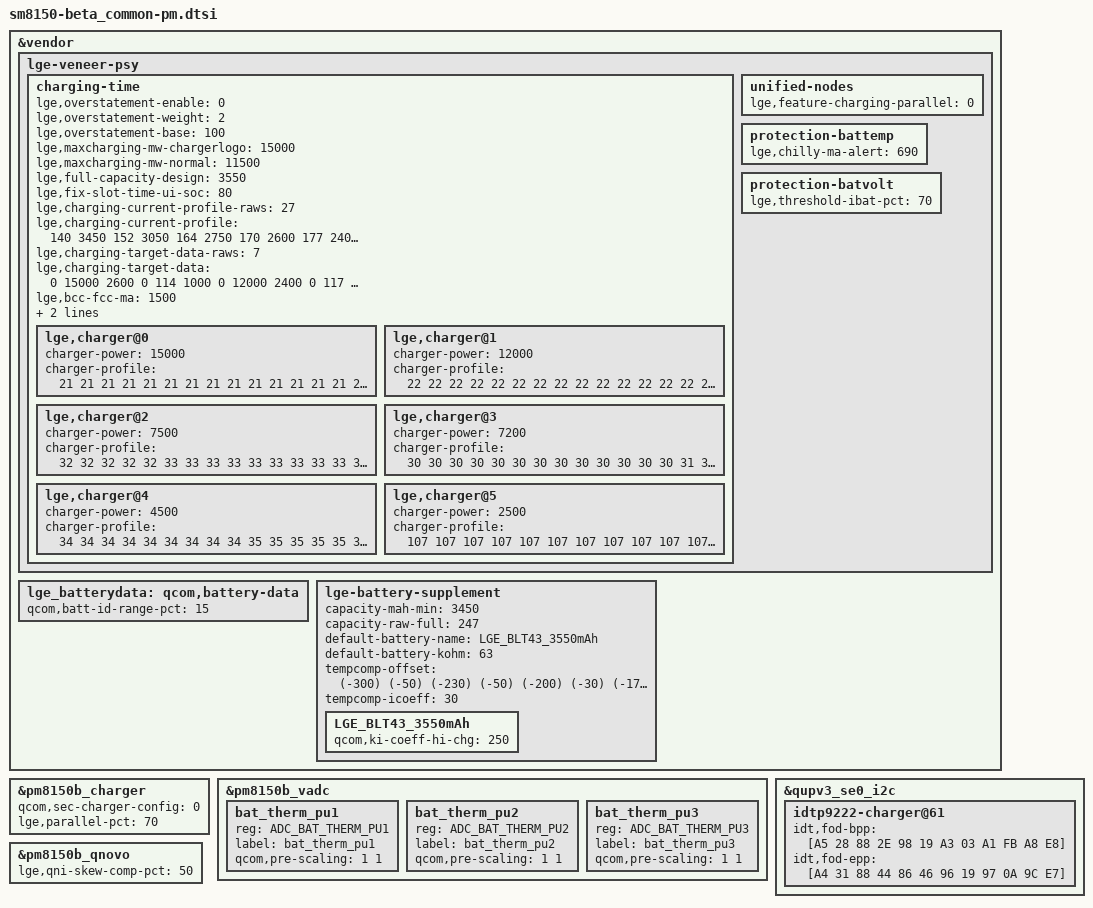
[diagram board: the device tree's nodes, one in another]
/*
 * Copyright (c) 2018, The Linux Foundation. All rights reserved.
 *
 * This program is free software; you can redistribute it and/or modify
 * it under the terms of the GNU General Public License version 2 and
 * only version 2 as published by the Free Software Foundation.
 *
 * This program is distributed in the hope that it will be useful,
 * but WITHOUT ANY WARRANTY; without even the implied warranty of
 * MERCHANTABILITY or FITNESS FOR A PARTICULAR PURPOSE.  See the
 * GNU General Public License for more details.
 */
#include "../../sm8150_common/sm8150_common-pm.dtsi"
&vendor {
	lge-veneer-psy {
		charging-time {
			#address-cells = <1>;
			#size-cells = <0>;
			lge,overstatement-enable = <0>;
			lge,overstatement-weight = <2>;
			lge,overstatement-base = <100>;

			lge,maxcharging-mw-chargerlogo = <15000>;
			lge,maxcharging-mw-normal = <11500>;

			lge,full-capacity-design = <3550>;
			lge,fix-slot-time-ui-soc = <80>;
			lge,charging-current-profile-raws = <27>;
			lge,charging-current-profile = <
				/* format: raw_soc, raw_current(mA) */
				/* CC */
				140  3450
				152  3050
				164  2750
				170  2600
				177  2400
				191  2100
				207  1650
				219  1300
				225  1100
				228  1050
				231  900
				/* cv - ui 94% */
				232  880
				233  860
				234  840
				235  810
				236  790
				237  735
				238  690
				239  660
				240  640
				241  615
				242  560
				243  530
				244  505
				245  470
				246  450
				247  430   /* <- END -> */
			>;

			lge,charging-target-data-raws = <7>;
			lge,charging-target-data = <
			/* format : type, power(mW), current(mA), down(uA), target(min), no_dd_decipct */
			/* type-wired: chargerlogo */   0    15000    2600       0    114    1000
			/* type-wired: power on    */   0    12000    2400       0    117    1000
			/* type-wired: DCP         */   0     7500    1650    1100    154    1000
			/* type-wired: SDP         */   0     2500     500       0    435    1000
			/* type-wireless: EPP      */   1     7200    1480    4100    205    1000
			/* type-wireless: BPP      */   1     4500    1060    2600    230    1000
			/* type-BCC                */   2     7500    1500       0    157    1000
			>;


			// BCC
			lge,bcc-fcc-ma = <1500>;
			bcc-charger-profile = <
				35  35  35  35  35  35  35  35  35  35  35  35  35  35  35  35
				35  35  35  35  35  35  35  35  35  35  35  35  35  35  35  35
				35  35  35  35  35  35  35  35  35  35  35  35  35  35  35  35
				35  35  35  35  35  35  35  35  35  35  35  35  35  35  35  35
				35  35  35  35  35  35  35  35  35  35  35  35  35  35  35  35
				35  35  35  35  35  35  35  35  35  35  35  35  35  35  35  35
				35  35  35  35  35  35  35  35  35  35  35  35  35  35  35  35
				35  35  35  35  35  35  35  35  35  35  35  35  35  35  35  35
				35  35  35  35  35  35  35  35  35  35  35  35  35  35  35  35
				35  35  35  35  35  35  35  35  35  35  35  35  35  35  35  35
				35  35  35  35  35  35  35  35  35  35  35  35  35  35  35  35
				35  35  35  35  35  35  35  35  35  35  35  35  35  35  35  35
				35  35  35  35  35  35  35  35  35  35  35  35  35  35  35  35
				35  35  35  35  35  35  35  36  37  38  39  40  41  42  43  45
				46  47  49  51  52  54  56  58  60  63  66  68  72  75  79  83
				88  93  99 106 114 123 134 148 148 148 148 148 148 148 148 148
			>;

			lge,charger@0 {		//  fast charger: 9V * 1.66A or 5V * 3A = 15W
				charger-power = <15000>;
				charger-profile = <
					21  21  21  21  21  21  21  21  21  21  21  21  21  21  21  21
					21  21  21  21  21  21  21  21  21  21  21  21  21  21  21  21
					21  21  21  21  21  21  21  21  21  21  21  21  21  21  21  21
					21  21  21  21  21  21  21  21  21  21  21  21  21  21  21  21
					21  21  21  21  21  21  21  21  21  21  21  21  21  21  21  21
					21  21  21  21  21  21  21  21  21  21  21  21  21  21  21  21
					21  21  21  21  21  21  21  21  21  21  21  21  21  21  21  21
					21  21  21  21  21  21  21  21  21  21  21  21  21  21  21  21
					21  21  21  21  21  21  21  21  21  21  21  21  21  21  21  21
					23  23  23  23  23  23  23  23  23  23  23  23  23  23  23  23
					23  23  23  23  23  23  23  23  23  23  23  23  23  23  23  23
					23  23  26  26  26  26  26  26  26  26  26  26  26  26  26  26
					33  33  33  33  33  33  33  33  33  33  33  33  33  33  33  33
					33  33  42  42  42  42  42  42  42  42  42  42  42  49  49  49
					49  49  49  51  60  61  63  64  66  68  69  71  73  75  77  79
					82  84  87  90  93  96 100 104 104 104 104 104 104 104 104 104
				>;
			};
			lge,charger@1 {		//  power-on fast charger: 2.4A * 4.0V / 80% = 12W
				charger-power = <12000>;
				charger-profile = <
					22  22  22  22  22  22  22  22  22  22  22  22  22  22  22  22
					22  22  22  22  22  22  22  22  22  22  22  22  22  22  22  22
					22  22  22  22  22  22  22  22  22  22  22  22  22  22  22  22
					22  22  22  22  22  22  22  22  22  22  22  22  22  22  22  22
					22  22  22  22  22  22  22  22  22  22  22  22  22  22  22  22
					22  22  22  22  22  22  22  22  22  22  22  22  22  22  22  22
					22  22  22  22  22  22  22  22  22  22  22  22  22  22  22  22
					22  22  22  22  22  22  22  22  22  22  22  22  22  22  22  22
					22  22  22  22  22  22  22  22  22  22  22  22  22  22  22  22
					22  22  22  22  22  22  22  22  22  22  22  22  22  22  22  22
					22  22  22  22  22  22  22  22  22  22  22  22  22  22  22  22
					22  22  26  26  26  26  26  26  26  26  26  26  26  26  26  26
					33  33  33  33  33  33  33  33  33  33  33  33  33  33  33  33
					41  41  41  41  41  41  41  41  41  41  41  49  49  49  49  49
					49  51  51  51  60  61  63  64  66  67  69  71  73  75  77  79
					81  84  87  90  93  96 100 103 103 103 103 103 103 103 103 103
				>;
			};
			lge,charger@2 {		//  dcp charger: 5V * 1500mA = 7.5W
				charger-power = <7500>;
				charger-profile = <
					32  32  32  32  32  33  33  33  33  33  33  33  33  33  33  33
					33  33  33  33  33  33  33  33  33  33  33  33  33  33  33  33
					33  33  33  33  33  33  33  33  33  33  33  33  33  33  33  33
					33  33  33  33  33  33  33  33  33  33  33  34  34  34  34  34
					34  34  34  34  34  34  34  34  34  34  34  34  34  34  34  34
					34  34  34  34  34  34  34  34  34  34  34  34  34  34  34  34
					34  34  34  34  34  34  34  34  34  34  34  34  34  35  35  35
					35  35  35  35  35  35  35  35  35  35  35  35  35  35  35  35
					35  35  35  35  35  35  35  35  35  35  35  35  35  35  35  35
					35  35  35  35  35  35  35  35  35  35  35  35  35  36  36  36
					36  36  36  36  36  36  36  36  36  36  36  36  36  36  36  36
					36  36  36  36  36  36  36  36  36  36  36  36  36  36  36  36
					36  36  36  36  36  36  36  36  36  36  37  37  37  37  37  37
					37  37  37  37  37  37  37  37  38  39  40  41  42  43  44  45
					47  48  50  51  53  55  57  59  61  64  66  69  73  76  80  84
					89  94 100 107 115 124 135 150 150 150 150 150 150 150 150 150
				>;
			};
			lge,charger@3 {		// EPP wireless charger: 9000mV * 800mA = 7.2W
				charger-power = <7200>;
				charger-profile = <
					30  30  30  30  30  30  30  30  30  30  30  30  30  31  31  31
					31  31  31  31  31  31  31  31  31  32  32  32  32  32  32  32
					32  32  32  32  33  33  33  33  33  33  33  33  33  33  34  34
					34  34  34  34  34  34  34  35  35  35  35  35  35  35  35  35
					36  36  36  36  36  36  36  36  36  37  37  37  37  37  37  37
					37  38  38  38  38  38  38  38  39  39  39  39  39  39  39  39
					40  40  40  40  40  40  41  41  41  41  41  41  41  42  42  42
					42  42  42  43  43  43  43  43  43  44  44  44  44  44  44  45
					45  45  45  45  46  46  46  46  46  47  47  47  47  47  48  48
					48  48  48  49  49  49  49  49  50  50  50  50  51  51  51  51
					52  52  52  52  53  53  53  53  54  54  54  54  55  55  55  55
					56  56  56  57  57  57  57  58  58  58  59  59  59  60  60  60
					61  61  61  62  62  62  63  63  63  64  64  65  65  65  66  66
					67  67  67  68  68  69  69  69  70  70  71  71  72  72  73  73
					74  74  75  75  76  76  77  77  78  78  79  80  80  81  81  82
					83  83  84  84  85  86  86  87  87  87  87  87  87  87  87  87
				>;
			};
			lge,charger@4 {		// BPP wireless charger: 6V * 750mA = 4.5W
				charger-power = <4500>;
				charger-profile = <
					34  34  34  34  34  34  34  34  34  35  35  35  35  35  35  35
					35  35  35  35  36  36  36  36  36  36  36  36  36  36  37  37
					37  37  37  37  37  37  37  37  38  38  38  38  38  38  38  38
					38  39  39  39  39  39  39  39  39  39  40  40  40  40  40  40
					40  40  41  41  41  41  41  41  41  41  42  42  42  42  42  42
					42  43  43  43  43  43  43  43  43  44  44  44  44  44  44  44
					45  45  45  45  45  45  46  46  46  46  46  46  47  47  47  47
					47  47  48  48  48  48  48  48  49  49  49  49  49  49  50  50
					50  50  50  51  51  51  51  51  52  52  52  52  52  53  53  53
					53  53  54  54  54  54  55  55  55  55  55  56  56  56  56  57
					57  57  57  58  58  58  58  59  59  59  59  60  60  60  60  61
					61  61  62  62  62  62  63  63  63  64  64  64  65  65  65  66
					66  66  67  67  67  68  68  68  69  69  69  70  70  70  71  71
					72  72  72  73  73  74  74  74  75  75  76  76  76  77  77  78
					78  79  79  80  80  81  81  82  82  83  83  84  84  85  85  86
					86  87  88  88  89  89  90  91  91  91  91  91  91  91  91  91
				>;
			};
			lge,charger@5 {		// SDP: 5000mV * 500mA = 2.5W
				charger-power = <2500>;
				charger-profile = <
					107 107 107 107 107 107 107 107 107 107 107 107 107 107 107 107
					107 107 107 107 107 107 107 107 107 107 107 107 107 107 107 107
					107 107 107 107 107 107 107 107 107 107 107 107 107 107 107 107
					107 107 107 107 107 107 107 107 107 107 107 107 107 107 107 107
					107 107 107 107 107 107 107 107 107 107 107 107 107 107 107 107
					107 107 107 107 107 107 107 107 107 107 107 107 107 107 107 107
					107 107 107 107 107 107 107 107 107 107 107 107 107 107 107 107
					107 107 107 107 107 107 107 107 107 107 107 107 107 107 107 107
					107 107 107 107 107 107 107 107 107 107 107 107 107 107 107 107
					107 107 107 107 107 107 107 107 107 107 107 107 107 107 107 107
					107 107 107 107 107 107 107 107 107 107 107 107 107 107 107 107
					107 107 107 107 107 107 107 107 107 107 107 107 107 107 107 107
					107 107 107 107 107 107 107 107 107 107 107 107 107 107 107 107
					107 107 107 107 107 107 107 107 107 107 107 107 107 107 107 107
					107 107 107 107 107 107 107 107 107 107 107 107 107 107 107 107
					107 107 107 107 107 107 107 107 107 107 107 107 107 107 107 107
				>;
			};
		};

		unified-nodes {
			lge,feature-charging-parallel = <0>;
		};

		protection-battemp {
			lge,chilly-ma-alert = <690>;
		};

		protection-batvolt {
			lge,threshold-ibat-pct = <70>;
		};
	};

	lge_batterydata: qcom,battery-data {
		qcom,batt-id-range-pct = <15>;
		#include "../../battery_profile/LGE_BLT43_3550mAh.dtsi"
	};

	lge-battery-supplement {
		capacity-mah-min = <3450>;
		capacity-raw-full = <247>;

		default-battery-name = "LGE_BLT43_3550mAh";
		default-battery-kohm = <63>;

		/* format : (temp index) (temp delta) */
		tempcomp-offset = <
			(-300) (-50)
			(-230) (-50)
			(-200) (-30)
			(-170) (-10)
			(-120) (-10)
			( -60) (-20)
			( -10) (-20)
			   40  (-20)
			   80  (-10)
			  130  (-10)
			  170     0
			  220     0
			  260    10
			  310    10
			  370     0
			  420     0
			  480  (-10)
			  520     0
			  570     0
			  620     0
			  660    10
			  700    10
			  730    50
			  750    60
			  800   120
		>;
		tempcomp-icoeff = <30>;
		LGE_BLT43_3550mAh {
			qcom,ki-coeff-hi-chg = <250>;
		};
	};
};

&pm8150b_charger {
	qcom,sec-charger-config = <0>;
	lge,parallel-pct = <70>;
};

&pm8150b_vadc {
	bat_therm_pu1 {
		reg = <ADC_BAT_THERM_PU1>;
		label = "bat_therm_pu1";
		qcom,pre-scaling = <1 1>;
	};

	bat_therm_pu2 {
		reg = <ADC_BAT_THERM_PU2>;
		label = "bat_therm_pu2";
		qcom,pre-scaling = <1 1>;
	};

	bat_therm_pu3 {
		reg = <ADC_BAT_THERM_PU3>;
		label = "bat_therm_pu3";
		qcom,pre-scaling = <1 1>;
	};
};

&qupv3_se0_i2c {
	idtp9222-charger@61 {
		// FOD parameters
		idt,fod-bpp    = [A5 28 88 2E 98 19 A3 03 A1 FB A8 E8];
		idt,fod-epp    = [A4 31 88 44 86 46 96 19 97 0A 9C E7];
	};
};

&pm8150b_qnovo {
	lge,qni-skew-comp-pct = <50>;
};
